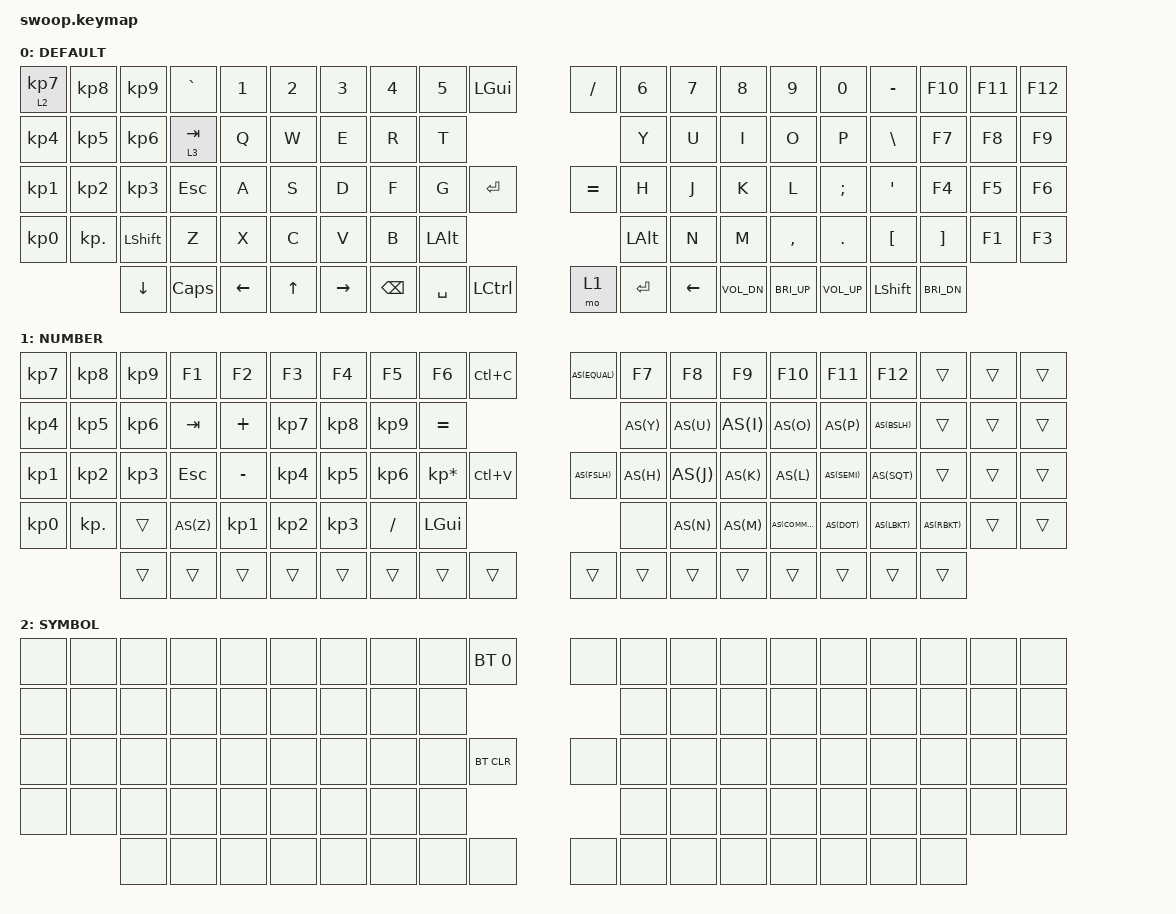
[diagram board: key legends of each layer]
#include <behaviors.dtsi>
#include <dt-bindings/zmk/keys.h>
#include <dt-bindings/zmk/rgb.h>
#include <dt-bindings/zmk/bt.h>
#include <dt-bindings/zmk/outputs.h>
#include <dt-bindings/zmk/ext_power.h>

#define DEFAULT 0
#define NUMBER  1
#define SYMBOL  2

#define AS(keycode) &as LS(keycode) keycode

/ {
  
       behaviors {
       as: auto_shift {
        compatible = "zmk,behavior-hold-tap";
        label = "AUTO_SHIFT";
        #binding-cells = <2>;
        tapping-term-ms = <160>;
        quick-tap-ms = <0>;
        flavor = "tap-preferred";
        bindings = <&kp>, <&kp>;
                };
modcp: mod_copy {
        compatible = "zmk,behavior-mod-morph";
        label = "MOD_COPY";
        #binding-cells = <0>;
        bindings = <&as LS(C) C>, <&kp C>;
        mods = <(MOD_LGUI | MOD_RGUI)>;
              };
  
        };


    macros {
        macro_phone: macro_phone {
            // 1351
            label = "MACRO_PHONE";
            compatible = "zmk,behavior-macro";
            #binding-cells = <0>;
            bindings
                = < &kp N1 &kp N3 &kp N5  &kp N1>
                ;
        };
        macro_email_q: macro_email_q {
            // 2894512440@qq.com
            label = "MACRO_EMAIL_QQ";
            compatible = "zmk,behavior-macro";
            #binding-cells = <0>;
            bindings 
                = < &kp N2 &kp N8 &kp N9 &kp N4 &kp N5 &kp  N1 &kp N2 &kp N4 &kp N4 &kp N0 
                    &kp AT &kp Q &kp Q &kp DOT  &kp C &kp O &kp M>
                ;
        };
        macro_email_g: macro_email_g {
            // 135115
            compatible = "zmk,behavior-macro";
            label = "MACRO_EMAIL_GMAIL";
            #binding-cells = <0>;
            bindings
                = < &kp N1 &kp N3 &kp N5  &kp N1 &kp N1 &kp N5 >
                ;
        };
       
    };
    



    keymap {
       compatible = "zmk,keymap";
        default_layer {
            label = "DEFAULT";
            bindings = <
  &lt 2 KP_N7 &kp KP_N8 &kp KP_N9 &kp GRAVE &kp N1 &kp N2 &kp N3 &kp N4 &kp N5    &kp LGUI    &kp FSLH  &kp N6  &kp N7  &kp N8  &kp N9  &kp N0  &kp MINUS &kp F10  &kp F11   &kp  F12 
   &kp KP_N4 &kp KP_N5 &kp KP_N6  &lt 3 TAB   &kp Q  &kp W    &kp E   &kp R   &kp T                   &kp Y  &kp U     &kp I     &kp O    &kp P    &kp BSLH  &kp F7 &kp F8  &kp F9
   &kp KP_N1 &kp KP_N2 &kp KP_N3 &kp ESC   &kp A  &kp S    &kp D   &kp F   &kp G  &kp ENTER    &kp EQUAL  &kp H  &kp J     &kp K     &kp L  &kp SEMI  &kp SQT    &kp F4 &kp F5 &kp F6
   &kp KP_N0 &kp KP_DOT &kp LSHFT  &kp Z  &kp X   &kp C   &kp V    &kp B   &kp LALT              &kp LALT  &kp N  &kp M     &kp COMMA &kp DOT    &kp LBKT  &kp RBKT    &kp F1 &kp F3 
       &kp DOWN &kp CAPSLOCK  &kp LEFT &kp UP &kp RIGHT &kp BSPC &kp SPACE &kp LCTRL                          &mo 1 &kp ENTER &kp LEFT &kp C_VOL_DN  &kp C_BRI_UP &kp C_VOL_UP  &kp LSHFT &kp C_BRI_DN 
            >;
        };
            number_layer {
            label = "NUMBER";
            bindings = <
   &kp KP_N7 &kp KP_N8 &kp KP_N9   &kp F1 &kp F2 &kp F3 &kp F4 &kp F5  &kp F6 &kp LC(C)   AS(EQUAL) &kp F7 &kp F8 &kp F9 &kp F10     &kp F11   &kp F12  &trans &trans &trans  
     &kp KP_N4 &kp KP_N5 &kp KP_N6   &kp TAB  &kp PLUS &kp KP_N7 &kp KP_N8 &kp KP_N9  &kp EQUAL                      AS(Y) AS(U) AS(I) AS(O) AS(P) AS(BSLH)  &trans &trans &trans  
    &kp KP_N1 &kp KP_N2 &kp KP_N3   &kp ESC  &kp MINUS  &kp KP_N4 &kp KP_N5 &kp KP_N6  &kp KP_MULTIPLY &kp LC(V)       AS(FSLH) AS(H)  AS(J) AS(K) AS(L) AS(SEMI) AS(SQT)  &trans &trans &trans  
   &kp KP_N0 &kp KP_DOT          &trans   AS(Z) &kp KP_N1 &kp KP_N2 &kp KP_N3 &kp FSLH  &kp LGUI             &none AS(N) AS(M) AS(COMMA) AS(DOT) AS(LBKT) AS(RBKT)   &trans &trans  
         &trans  &trans  &trans   &trans  &trans  &trans   &trans  &trans                       &trans  &trans  &trans   &trans  &trans  &trans   &trans  &trans  
            >;
        };
                     
        symbol_layer {
            label = "SYMBOL";
            bindings = <
    &none     &none   &none   &none   &none   &none     &none     &none   &none   &bt BT_SEL 0   &none   &none       &none     &none   &none   &none   &none   &none   &none   &none
    &none     &none   &none   &none   &none   &none     &none     &none   &none   &none         &none     &none   &none   &none   &none   &none     &none     &none  
  &none     &none   &none   &none   &none   &none     &none     &none   &none   &bt BT_CLR         &none     &none   &none   &none   &none   &none     &none     &none   &none   &none 
    &none     &none   &none   &none   &none   &none     &none     &none   &none   &none   &none   &none   &none   &none   &none           &none   &none &none 
       &none     &none   &none   &none   &none   &none     &none     &none   &none   &none     &none     &none     &none   &none   &none      &none  
            >;
        };
         
   };
};
